AUTOSAR XML (schema 00046)
package /ComponentTypes
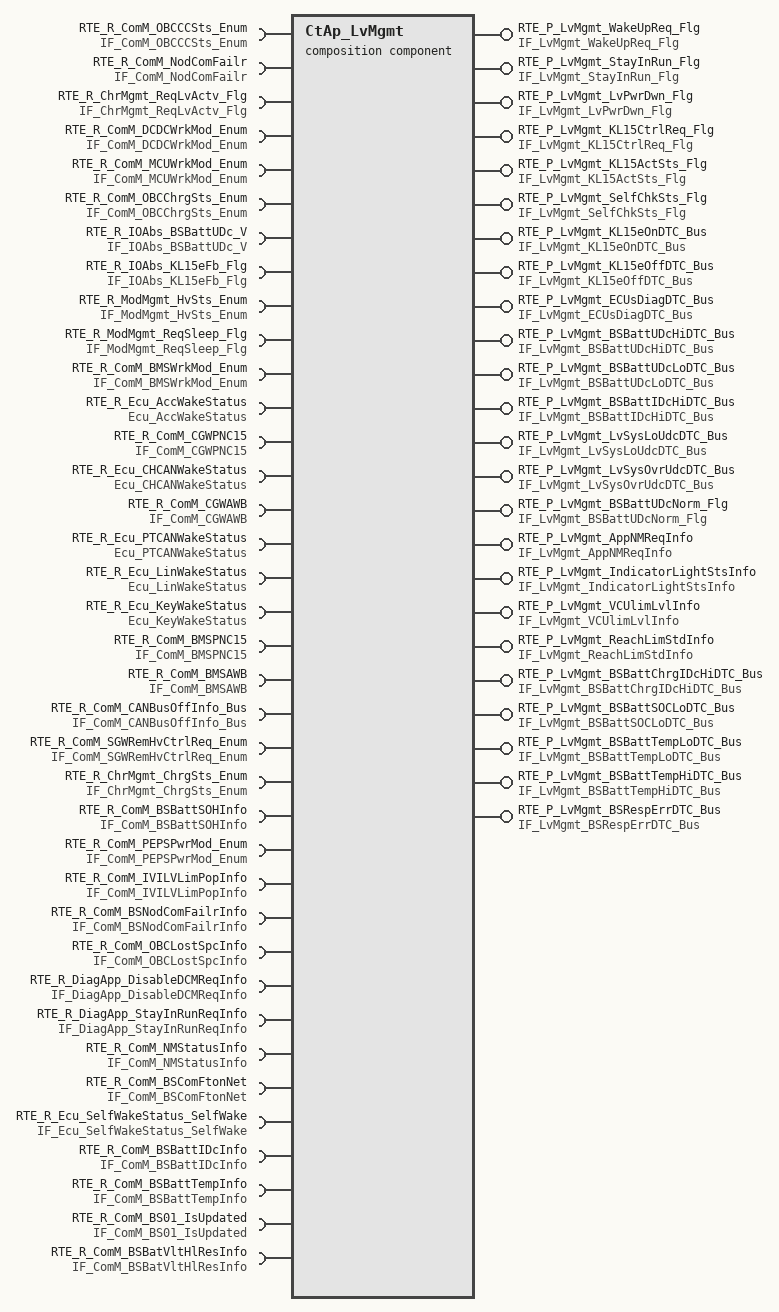
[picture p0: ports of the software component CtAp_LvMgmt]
  composition sw component type CtAp_LvMgmt
    provide port RTE_P_LvMgmt_WakeUpReq_Flg: nonqueued-sender-com-spec{data-element=tec_LvMgmt_WakeUpReq_Flg, init-value=0}, provided-interface=IF_LvMgmt_WakeUpReq_Flg
    require port RTE_R_ComM_OBCCCSts_Enum: nonqueued-receiver-com-spec{data-element=tec_ComM_OBCCCSts_Enum, filter=data-filter-type=ALWAYS, init-value=0}, required-interface=IF_ComM_OBCCCSts_Enum
    require port RTE_R_ComM_NodComFailr: required-interface=IF_ComM_NodComFailr
      required-com-specs:
        data-element=tec_ComM_SGWNodComFailr_Flg, filter=data-filter-type=ALWAYS, init-value=0
        data-element=tec_ComM_CGWNodComFailr_Flg, filter=data-filter-type=ALWAYS, init-value=0
        data-element=tec_ComM_TCUNodComFailr_Flg, filter=data-filter-type=ALWAYS, init-value=0
        data-element=tec_ComM_BCMNodComFailr_Flg, filter=data-filter-type=ALWAYS, init-value=0
        data-element=tec_ComM_PRNDNodComFailr_Flg, filter=data-filter-type=ALWAYS, init-value=0
        data-element=tec_ComM_IVINodComFailr_Flg, filter=data-filter-type=ALWAYS, init-value=0
        data-element=tec_ComM_DCDCNodComFailr_Flg, filter=data-filter-type=ALWAYS, init-value=0
        data-element=tec_ComM_OBCNodComFailr_Flg, filter=data-filter-type=ALWAYS, init-value=0
        data-element=tec_ComM_CHIBSNodComFailr_Flg, filter=data-filter-type=ALWAYS, init-value=0
        data-element=tec_ComM_MCUNodComFailr_Flg, filter=data-filter-type=ALWAYS, init-value=0
        data-element=tec_ComM_EVCOMNodComFailr_Flg, filter=data-filter-type=ALWAYS, init-value=0
        data-element=tec_ComM_EPTIBSNodComFailr_Flg, filter=data-filter-type=ALWAYS, init-value=0
        data-element=tec_ComM_DCMNodComFailr_Flg, filter=data-filter-type=ALWAYS, init-value=0
        data-element=tec_ComM_BMSNodComFailr_Flg, filter=data-filter-type=ALWAYS, init-value=0
        data-element=tec_ComM_ACUNodComFailr_Flg, filter=data-filter-type=ALWAYS, init-value=0
        data-element=tec_ComM_APTCNodComFailr_Flg, filter=data-filter-type=ALWAYS, init-value=0
        data-element=tec_ComM_ADCUNodComFailr_Flg, filter=data-filter-type=ALWAYS, init-value=0
        data-element=tec_ComM_DCMRRNodComFailr_Flg, filter=data-filter-type=ALWAYS, init-value=0
        data-element=tec_ComM_DCMRLNodComFailr_Flg, filter=data-filter-type=ALWAYS, init-value=0
        data-element=tec_ComM_DCMFRNodComFailr_Flg, filter=data-filter-type=ALWAYS, init-value=0
        data-element=tec_ComM_DCMFLNodComFailr_Flg, filter=data-filter-type=ALWAYS, init-value=0
        data-element=tec_ComM_SGWCHNodComFailr_Flg, filter=data-filter-type=ALWAYS, init-value=0
    require port RTE_R_ChrMgmt_ReqLvActv_Flg: nonqueued-receiver-com-spec{data-element=tec_ChrMgmt_ReqLvActv_Flg, filter=data-filter-type=ALWAYS, init-value=0}, required-interface=IF_ChrMgmt_ReqLvActv_Flg
    13 x provide port:
      RTE_P_LvMgmt_StayInRun_Flg: nonqueued-sender-com-spec{data-element=tec_LvMgmt_StayInRun_Flg, init-value=0}, provided-interface=IF_LvMgmt_StayInRun_Flg
      RTE_P_LvMgmt_LvPwrDwn_Flg: nonqueued-sender-com-spec{data-element=tec_LvMgmt_LvPwrDwn_Flg, init-value=0}, provided-interface=IF_LvMgmt_LvPwrDwn_Flg
      RTE_P_LvMgmt_KL15CtrlReq_Flg: nonqueued-sender-com-spec{data-element=tec_LvMgmt_KL15CtrlReq_Flg, init-value=0}, provided-interface=IF_LvMgmt_KL15CtrlReq_Flg
      RTE_P_LvMgmt_KL15ActSts_Flg: nonqueued-sender-com-spec{data-element=tec_LvMgmt_KL15ActSts_Flg, init-value=0}, provided-interface=IF_LvMgmt_KL15ActSts_Flg
      RTE_P_LvMgmt_SelfChkSts_Flg: nonqueued-sender-com-spec{data-element=tec_LvMgmt_SelfChkSts_Flg, init-value=0}, provided-interface=IF_LvMgmt_SelfChkSts_Flg
      RTE_P_LvMgmt_KL15eOnDTC_Bus: nonqueued-sender-com-spec{data-element=tec_LvMgmt_KL15eOnDTC_Bus, init-value=fields=[LvMgmt_MonStatKL15eOnDTC_:0, LvMgmt_MonResKL15eOnDTC:0, LvMgmt_ErrStatKL15eOnDTC:0, LvMgmt_ErrResKL15eOnDTC:0]}, provided-interface=IF_LvMgmt_KL15eOnDTC_Bus
      RTE_P_LvMgmt_KL15eOffDTC_Bus: nonqueued-sender-com-spec{data-element=tec_LvMgmt_KL15eOffDTC_Bus, init-value=fields=[LvMgmt_MonStatKL15eOffDTC:0, LvMgmt_MonResKL15eOffDTC:0, LvMgmt_ErrStatKL15eOffDTC:0, LvMgmt_ErrResKL15eOffDTC:0]}, provided-interface=IF_LvMgmt_KL15eOffDTC_Bus
      RTE_P_LvMgmt_ECUsDiagDTC_Bus: nonqueued-sender-com-spec{data-element=tec_LvMgmt_ECUsDiagDTC_Bus, init-value=fields=[LvMgmt_MonStatECUsDiagDTC:0, LvMgmt_MonResECUsDiagDTC:0, LvMgmt_ErrStatECUsDiagDTC:0, LvMgmt_ErrResECUsDiagDTC:0]}, provided-interface=IF_LvMgmt_ECUsDiagDTC_Bus
      RTE_P_LvMgmt_BSBattUDcHiDTC_Bus: nonqueued-sender-com-spec{data-element=tec_LvMgmt_BSBattUDcHiDTC_Bus, init-value=fields=[LvMgmt_MonStatBSBattUDcHiDTC:0, LvMgmt_MonResBSBattUDcHiDTC:0, LvMgmt_ErrStatBSBattUDcHiDTC:0, LvMgmt_ErrResBSBattUDcHiDTC:0]}, provided-interface=IF_LvMgmt_BSBattUDcHiDTC_Bus
      RTE_P_LvMgmt_BSBattUDcLoDTC_Bus: nonqueued-sender-com-spec{data-element=tec_LvMgmt_BSBattUDcLoDTC_Bus, init-value=fields=[LvMgmt_MonStatBSBattUDcLoDTC:0, LvMgmt_MonResBSBattUDcLoDTC:0, LvMgmt_ErrStatBSBattUDcLoDTC:0, LvMgmt_ErrResBSBattUDcLoDTC:0]}, provided-interface=IF_LvMgmt_BSBattUDcLoDTC_Bus
      RTE_P_LvMgmt_BSBattIDcHiDTC_Bus: nonqueued-sender-com-spec{data-element=tec_LvMgmt_BSBattIDcHiDTC_Bus, init-value=fields=[LvMgmt_MonStatBSBattIDcHiDTC:0, LvMgmt_MonResBSBattIDcHiDTC:0, LvMgmt_ErrStatBSBattIDcHiDTC:0, LvMgmt_ErrResBSBattIDcHiDTC:0]}, provided-interface=IF_LvMgmt_BSBattIDcHiDTC_Bus
      RTE_P_LvMgmt_LvSysLoUdcDTC_Bus: nonqueued-sender-com-spec{data-element=tec_LvMgmt_LvSysLoUdcDTC_Bus, init-value=fields=[LvMgmt_MonStatLvSysLoUDcDTC:0, LvMgmt_MonResLvSysLoUDcDTC:0, LvMgmt_ErrStatLvSysLoUDcDTC:0, LvMgmt_ErrResLvSysLoUDcDTC:0]}, provided-interface=IF_LvMgmt_LvSysLoUdcDTC_Bus
      RTE_P_LvMgmt_LvSysOvrUdcDTC_Bus: nonqueued-sender-com-spec{data-element=tec_LvMgmt_LvSysOvrUdcDTC_Bus, init-value=fields=[LvMgmt_MonStatLvSysOvrUDcDTC:0, LvMgmt_MonResLvSysOvrUDcDTC:0, LvMgmt_ErrStatLvSysOvrUDcDTC:0, LvMgmt_ErrResLvSysOvrUDcDTC:0]}, provided-interface=IF_LvMgmt_LvSysOvrUdcDTC_Bus
    8 x require port:
      RTE_R_ComM_DCDCWrkMod_Enum: nonqueued-receiver-com-spec{data-element=tec_ComM_DCDCWrkMod_Enum, filter=data-filter-type=ALWAYS, init-value=0}, required-interface=IF_ComM_DCDCWrkMod_Enum
      RTE_R_ComM_MCUWrkMod_Enum: nonqueued-receiver-com-spec{data-element=tec_ComM_MCUWrkMod_Enum, filter=data-filter-type=ALWAYS, init-value=0}, required-interface=IF_ComM_MCUWrkMod_Enum
      RTE_R_ComM_OBCChrgSts_Enum: nonqueued-receiver-com-spec{data-element=tec_ComM_OBCChrgSts_Enum, filter=data-filter-type=ALWAYS, init-value=0}, required-interface=IF_ComM_OBCChrgSts_Enum
      RTE_R_IOAbs_BSBattUDc_V: nonqueued-receiver-com-spec{data-element=tec_IOAbs_BSBattUDc_V, filter=data-filter-type=ALWAYS, init-value=0}, required-interface=IF_IOAbs_BSBattUDc_V
      RTE_R_IOAbs_KL15eFb_Flg: nonqueued-receiver-com-spec{data-element=tec_IOAbs_KL15eFb_Flg, filter=data-filter-type=ALWAYS, init-value=0}, required-interface=IF_IOAbs_KL15eFb_Flg
      RTE_R_ModMgmt_HvSts_Enum: nonqueued-receiver-com-spec{data-element=tec_ModMgmt_HvSts_Enum, filter=data-filter-type=ALWAYS, init-value=0}, required-interface=IF_ModMgmt_HvSts_Enum
      RTE_R_ModMgmt_ReqSleep_Flg: nonqueued-receiver-com-spec{data-element=tec_ModMgmt_ReqSleep_Flg, filter=data-filter-type=ALWAYS, init-value=0}, required-interface=IF_ModMgmt_ReqSleep_Flg
      RTE_R_ComM_BMSWrkMod_Enum: nonqueued-receiver-com-spec{data-element=tec_ComM_BMSWrkMod_Enum, filter=data-filter-type=ALWAYS, init-value=0}, required-interface=IF_ComM_BMSWrkMod_Enum
    provide port RTE_P_LvMgmt_BSBattUDcNorm_Flg: nonqueued-sender-com-spec{data-element=tec_LvMgmt_BSBattUDcNorm_Flg, init-value=0}, provided-interface=IF_LvMgmt_BSBattUDcNorm_Flg
    10 x require port:
      RTE_R_Ecu_AccWakeStatus: nonqueued-receiver-com-spec{data-element=Accwake, filter=data-filter-type=ALWAYS, init-value=0}, required-interface=Ecu_AccWakeStatus
      RTE_R_ComM_CGWPNC15: nonqueued-receiver-com-spec{data-element=tec_ComM_CGWPNC15, filter=data-filter-type=ALWAYS, init-value=0}, required-interface=IF_ComM_CGWPNC15
      RTE_R_Ecu_CHCANWakeStatus: nonqueued-receiver-com-spec{data-element=CHCANwake, filter=data-filter-type=ALWAYS, init-value=0}, required-interface=Ecu_CHCANWakeStatus
      RTE_R_ComM_CGWAWB: nonqueued-receiver-com-spec{data-element=tec_ComM_CGWAWB, filter=data-filter-type=ALWAYS, init-value=0}, required-interface=IF_ComM_CGWAWB
      RTE_R_Ecu_PTCANWakeStatus: nonqueued-receiver-com-spec{data-element=PTCANwake, filter=data-filter-type=ALWAYS, init-value=0}, required-interface=Ecu_PTCANWakeStatus
      RTE_R_Ecu_LinWakeStatus: nonqueued-receiver-com-spec{data-element=Linwake, filter=data-filter-type=ALWAYS, init-value=0}, required-interface=Ecu_LinWakeStatus
      RTE_R_Ecu_KeyWakeStatus: nonqueued-receiver-com-spec{data-element=Keywake, filter=data-filter-type=ALWAYS, init-value=0}, required-interface=Ecu_KeyWakeStatus
      RTE_R_ComM_BMSPNC15: nonqueued-receiver-com-spec{data-element=tec_ComM_BMSPNC15, filter=data-filter-type=ALWAYS, init-value=0}, required-interface=IF_ComM_BMSPNC15
      RTE_R_ComM_BMSAWB: nonqueued-receiver-com-spec{data-element=tec_ComM_BMSAWB, filter=data-filter-type=ALWAYS, init-value=0}, required-interface=IF_ComM_BMSAWB
      RTE_R_ComM_CANBusOffInfo_Bus: required-interface=IF_ComM_CANBusOffInfo_Bus
        required-com-specs:
          data-element=tec_ComM_EPTCANBusOffInfo_Bus, filter=data-filter-type=ALWAYS, init-value=fields=[ComM_MonStatEPTCANBusOffInfo:0, ComM_MonResEPTCANBusOffInfo:0, ComM_ErrStatEPTCANBusOffInfo:0, ComM_ErrResEPTCANBusOffInfo:0]
          data-element=tec_ComM_CHCANBusOffInfo_Bus, filter=data-filter-type=ALWAYS, init-value=fields=[ComM_MonStatCHCANBusOffInfo:0, ComM_MonResCHCANBusOffInfo:0, ComM_ErrStatCHCANBusOffInfo:0, ComM_ErrResCHCANBusOffInfo:0]
          data-element=tec_ComM_EPTCANBusOffDTCInfo_Bus, filter=data-filter-type=ALWAYS, init-value=fields=[ComM_MonStatEPTCANBusOffDTCInfo:0, ComM_MonResEPTCANBusOffDTCInfo:0, ComM_ErrStatEPTCANBusOffDTCInfo:0, ComM_ErrResEPTCANBusOffDTCInfo:0]
          data-element=tec_ComM_CHCANBusOffDTCInfo_Bus, filter=data-filter-type=ALWAYS, init-value=fields=[ComM_MonStatCHCANBusOffDTCInfo:0, ComM_MonResCHCANBusOffDTCInfo:0, ComM_ErrStatCHCANBusOffDTCInfo:0, ComM_ErrResCHCANBusOffDTCInfo:0]
          data-element=tec_ComM_DCCANBusOffDTCInfo_Bus, filter=data-filter-type=ALWAYS
          data-element=tec_ComM_DCCANBusOffInfo_Bus, filter=data-filter-type=ALWAYS
    provide port RTE_P_LvMgmt_AppNMReqInfo: nonqueued-sender-com-spec{data-element=tec_LvMgmt_AppNMReqInfo, init-value=0}, provided-interface=IF_LvMgmt_AppNMReqInfo
    6 x require port:
      RTE_R_ComM_SGWRemHvCtrlReq_Enum: nonqueued-receiver-com-spec{data-element=tec_ComM_SGWRemHvCtrlReq_Enum, filter=data-filter-type=ALWAYS, init-value=0}, required-interface=IF_ComM_SGWRemHvCtrlReq_Enum
      RTE_R_ChrMgmt_ChrgSts_Enum: nonqueued-receiver-com-spec{data-element=tec_ChrMgmt_ChrgSts_Enum, filter=data-filter-type=ALWAYS, init-value=0}, required-interface=IF_ChrMgmt_ChrgSts_Enum
      RTE_R_ComM_BSBattSOHInfo: nonqueued-receiver-com-spec{data-element=tec_ComM_BSBattSOHInfo, filter=data-filter-type=ALWAYS, init-value=0}, required-interface=IF_ComM_BSBattSOHInfo
      RTE_R_ComM_PEPSPwrMod_Enum: nonqueued-receiver-com-spec{data-element=tec_ComM_PEPSPwrMod_Enum, filter=data-filter-type=ALWAYS, init-value=0}, required-interface=IF_ComM_PEPSPwrMod_Enum
      RTE_R_ComM_IVILVLimPopInfo: nonqueued-receiver-com-spec{data-element=tec_ComM_IVILVLimPopInfo, filter=data-filter-type=ALWAYS, init-value=0}, required-interface=IF_ComM_IVILVLimPopInfo
      RTE_R_ComM_BSNodComFailrInfo: nonqueued-receiver-com-spec{data-element=tec_ComM_BSNodComFailrInfo, filter=data-filter-type=ALWAYS, init-value=0}, required-interface=IF_ComM_BSNodComFailrInfo
    provide port RTE_P_LvMgmt_IndicatorLightStsInfo: nonqueued-sender-com-spec{data-element=tec_LvMgmt_IndicatorLightStsInfo, init-value=0}, provided-interface=IF_LvMgmt_IndicatorLightStsInfo
    provide port RTE_P_LvMgmt_VCUlimLvlInfo: nonqueued-sender-com-spec{data-element=tec_LvMgmt_VCUlimLvlInfo, init-value=0}, provided-interface=IF_LvMgmt_VCUlimLvlInfo
    provide port RTE_P_LvMgmt_ReachLimStdInfo: nonqueued-sender-com-spec{data-element=tec_LvMgmt_ReachLimStdInfo, init-value=0}, provided-interface=IF_LvMgmt_ReachLimStdInfo
    4 x require port:
      RTE_R_ComM_OBCLostSpcInfo: nonqueued-receiver-com-spec{data-element=tec_ComM_OBCLostSpcInfo, filter=data-filter-type=ALWAYS, init-value=0}, required-interface=IF_ComM_OBCLostSpcInfo
      RTE_R_DiagApp_DisableDCMReqInfo: nonqueued-receiver-com-spec{data-element=tec_DiagApp_DisableDCMReqInfo, filter=data-filter-type=ALWAYS, init-value=0}, required-interface=IF_DiagApp_DisableDCMReqInfo
      RTE_R_DiagApp_StayInRunReqInfo: nonqueued-receiver-com-spec{data-element=tec_DiagApp_StayInRunReqInfo, filter=data-filter-type=ALWAYS, init-value=0}, required-interface=IF_DiagApp_StayInRunReqInfo
      RTE_R_ComM_NMStatusInfo: nonqueued-receiver-com-spec{data-element=tec_ComM_NMStatusInfo, filter=data-filter-type=ALWAYS, init-value=0}, required-interface=IF_ComM_NMStatusInfo
    5 x provide port:
      RTE_P_LvMgmt_BSBattChrgIDcHiDTC_Bus: nonqueued-sender-com-spec{data-element=tec_LvMgmt_BSBattChrgIDcHiDTC_Bus, init-value=fields=[LvMgmt_MonStatBSBattChrgIDcHiDTC:0, LvMgmt_MonResBSBattChrgIDcHiDTC:0, LvMgmt_ErrStatBSBattChrgIDcHiDTC:0, LvMgmt_ErrResBSBattChrgIDcHiDTC:0]}, provided-interface=IF_LvMgmt_BSBattChrgIDcHiDTC_Bus
      RTE_P_LvMgmt_BSBattSOCLoDTC_Bus: nonqueued-sender-com-spec{data-element=tec_LvMgmt_BSBattSOCLoDTC_Bus, init-value=fields=[LvMgmt_MonStatBSBattSOCLoDTC:0, LvMgmt_MonResBSBattSOCLoDTC:0, LvMgmt_ErrStatBSBattSOCLoDTC:0, LvMgmt_ErrResBSBattSOCLoDTC:0]}, provided-interface=IF_LvMgmt_BSBattSOCLoDTC_Bus
      RTE_P_LvMgmt_BSBattTempLoDTC_Bus: nonqueued-sender-com-spec{data-element=tec_LvMgmt_BSBattTempLoDTC_Bus, init-value=fields=[LvMgmt_MonStatBSBattTempLoDTC:0, LvMgmt_MonResBSBattTempLoDTC:0, LvMgmt_ErrStatBSBattTempLoDTC:0, LvMgmt_ErrResBSBattTempLoDTC:0]}, provided-interface=IF_LvMgmt_BSBattTempLoDTC_Bus
      RTE_P_LvMgmt_BSBattTempHiDTC_Bus: nonqueued-sender-com-spec{data-element=tec_LvMgmt_BSBattTempHiDTC_Bus, init-value=fields=[LvMgmt_MonStatBSBattTempHiDTC:0, LvMgmt_MonResBSBattTempHiDTC:0, LvMgmt_ErrStatBSBattTempHiDTC:0, LvMgmt_ErrResBSBattTempHiDTC:0]}, provided-interface=IF_LvMgmt_BSBattTempHiDTC_Bus
      RTE_P_LvMgmt_BSRespErrDTC_Bus: nonqueued-sender-com-spec{data-element=tec_LvMgmt_BSRespErrDTC_Bus, init-value=fields=[LvMgmt_MonStatBSRespErrDTC:0, LvMgmt_MonResBSRespErrDTC:0, LvMgmt_ErrStatBSRespErrDTC:0, LvMgmt_ErrResBSRespErrDTC:0]}, provided-interface=IF_LvMgmt_BSRespErrDTC_Bus
    6 x require port:
      RTE_R_ComM_BSComFtonNet: nonqueued-receiver-com-spec{data-element=tec_ComM_BSComFtonNet, filter=data-filter-type=ALWAYS, init-value=0}, required-interface=IF_ComM_BSComFtonNet
      RTE_R_Ecu_SelfWakeStatus_SelfWake: nonqueued-receiver-com-spec{data-element=tec_Ecu_SelfWakeStatus_SelfWake, filter=data-filter-type=ALWAYS, init-value=0}, required-interface=IF_Ecu_SelfWakeStatus_SelfWake
      RTE_R_ComM_BSBattIDcInfo: nonqueued-receiver-com-spec{data-element=tec_ComM_BSBattIDcInfo, filter=data-filter-type=ALWAYS, init-value=0}, required-interface=IF_ComM_BSBattIDcInfo
      RTE_R_ComM_BSBattTempInfo: nonqueued-receiver-com-spec{data-element=tec_ComM_BSBattTempInfo, filter=data-filter-type=ALWAYS, init-value=0}, required-interface=IF_ComM_BSBattTempInfo
      RTE_R_ComM_BS01_IsUpdated: nonqueued-receiver-com-spec{data-element=tec_ComM_BS01_IsUpdated, filter=data-filter-type=ALWAYS, init-value=0}, required-interface=IF_ComM_BS01_IsUpdated
      RTE_R_ComM_BSBatVltHlResInfo: nonqueued-receiver-com-spec{data-element=tec_ComM_BSBatVltHlResInfo, filter=data-filter-type=ALWAYS, init-value=0}, required-interface=IF_ComM_BSBatVltHlResInfo
    component CtAp_ElSSDiag: type=CtAp_ElSSDiag
    component CtAp_WakeUpRsn: type=CtAp_WakeUpRsn
    component CtAp_LvBattMgmt: type=CtAp_LvBattMgmt
    delegate CtAp_WakeUpRsn.RTE_P_LvMgmt_WakeUpReq_Flg <-> outer port RTE_P_LvMgmt_WakeUpReq_Flg
    delegate CtAp_WakeUpRsn.RTE_R_ComM_OBCCCSts_Enum <-> outer port RTE_R_ComM_OBCCCSts_Enum
    delegate CtAp_WakeUpRsn.RTE_R_ChrMgmt_ReqLvActv_Flg <-> outer port RTE_R_ChrMgmt_ReqLvActv_Flg
    delegate CtAp_ElSSDiag.RTE_R_IOAbs_KL15eFb_Flg <-> outer port RTE_R_IOAbs_KL15eFb_Flg
    delegate CtAp_ElSSDiag.RTE_R_ComM_DCDCWrkMod_Enum <-> outer port RTE_R_ComM_DCDCWrkMod_Enum
    delegate CtAp_ElSSDiag.RTE_R_ComM_OBCChrgSts_Enum <-> outer port RTE_R_ComM_OBCChrgSts_Enum
    delegate CtAp_ElSSDiag.RTE_R_ComM_MCUWrkMod_Enum <-> outer port RTE_R_ComM_MCUWrkMod_Enum
    delegate CtAp_ElSSDiag.RTE_R_ModMgmt_HvSts_Enum <-> outer port RTE_R_ModMgmt_HvSts_Enum
    delegate CtAp_ElSSDiag.RTE_R_ModMgmt_ReqSleep_Flg <-> outer port RTE_R_ModMgmt_ReqSleep_Flg
    connect CtAp_WakeUpRsn.RTE_P_LvMgmt_WakeUpReq_Flg -> CtAp_ElSSDiag.RTE_R_LvMgmt_WakeUpReq_Flg
    delegate CtAp_ElSSDiag.RTE_P_LvMgmt_StayInRun_Flg <-> outer port RTE_P_LvMgmt_StayInRun_Flg
    delegate CtAp_ElSSDiag.RTE_P_LvMgmt_KL15eOffDTC_Bus <-> outer port RTE_P_LvMgmt_KL15eOffDTC_Bus
    delegate CtAp_LvBattMgmt.RTE_P_LvMgmt_LvSysOvrUdcDTC_Bus <-> outer port RTE_P_LvMgmt_LvSysOvrUdcDTC_Bus
    delegate CtAp_ElSSDiag.RTE_P_LvMgmt_ECUsDiagDTC_Bus <-> outer port RTE_P_LvMgmt_ECUsDiagDTC_Bus
    delegate CtAp_ElSSDiag.RTE_P_LvMgmt_KL15eOnDTC_Bus <-> outer port RTE_P_LvMgmt_KL15eOnDTC_Bus
    delegate CtAp_ElSSDiag.RTE_P_LvMgmt_KL15CtrlReq_Flg <-> outer port RTE_P_LvMgmt_KL15CtrlReq_Flg
    delegate CtAp_LvBattMgmt.RTE_P_LvMgmt_BSBattUDcLoDTC_Bus <-> outer port RTE_P_LvMgmt_BSBattUDcLoDTC_Bus
    delegate CtAp_LvBattMgmt.RTE_P_LvMgmt_BSBattUDcHiDTC_Bus <-> outer port RTE_P_LvMgmt_BSBattUDcHiDTC_Bus
    delegate CtAp_ElSSDiag.RTE_P_LvMgmt_SelfChkSts_Flg <-> outer port RTE_P_LvMgmt_SelfChkSts_Flg
    delegate CtAp_LvBattMgmt.RTE_P_LvMgmt_BSBattIDcHiDTC_Bus <-> outer port RTE_P_LvMgmt_BSBattIDcHiDTC_Bus
    delegate CtAp_ElSSDiag.RTE_P_LvMgmt_LvPwrDwn_Flg <-> outer port RTE_P_LvMgmt_LvPwrDwn_Flg
    delegate CtAp_ElSSDiag.RTE_P_LvMgmt_KL15ActSts_Flg <-> outer port RTE_P_LvMgmt_KL15ActSts_Flg
    delegate CtAp_ElSSDiag.RTE_R_ComM_BMSWrkMod_Enum <-> outer port RTE_R_ComM_BMSWrkMod_Enum
    delegate CtAp_LvBattMgmt.RTE_P_LvMgmt_LvSysLoUdcDTC_Bus <-> outer port RTE_P_LvMgmt_LvSysLoUdcDTC_Bus
    delegate CtAp_LvBattMgmt.RTE_P_LvMgmt_BSBattUDcNorm_Flg <-> outer port RTE_P_LvMgmt_BSBattUDcNorm_Flg
    connect CtAp_LvBattMgmt.RTE_P_LvMgmt_BSBattUDcNorm_Flg -> CtAp_ElSSDiag.RTE_R_LvMgmt_BSBattUDcNorm_Flg
    delegate CtAp_LvBattMgmt.RTE_R_IOAbs_BSBattUDc_V <-> outer port RTE_R_IOAbs_BSBattUDc_V
    delegation sw connector RTE_R_ComM_BSBattSOC_pct_CtAp_LvBattMgmt_RTE_R_ComM_BSBattSOC_pct: inner-port=CtAp_LvBattMgmt.RTE_R_ComM_BSBattSOC_pct
    delegate CtAp_WakeUpRsn.RTE_R_Ecu_AccWakeStatus <-> outer port RTE_R_Ecu_AccWakeStatus
    delegate CtAp_WakeUpRsn.RTE_R_ComM_CGWPNC15 <-> outer port RTE_R_ComM_CGWPNC15
    delegate CtAp_WakeUpRsn.RTE_R_Ecu_CHCANWakeStatus <-> outer port RTE_R_Ecu_CHCANWakeStatus
    delegate CtAp_WakeUpRsn.RTE_R_ComM_CGWAWB <-> outer port RTE_R_ComM_CGWAWB
    delegate CtAp_WakeUpRsn.RTE_R_Ecu_PTCANWakeStatus <-> outer port RTE_R_Ecu_PTCANWakeStatus
    delegate CtAp_WakeUpRsn.RTE_R_Ecu_LinWakeStatus <-> outer port RTE_R_Ecu_LinWakeStatus
    delegate CtAp_WakeUpRsn.RTE_R_Ecu_KeyWakeStatus <-> outer port RTE_R_Ecu_KeyWakeStatus
    delegate CtAp_WakeUpRsn.RTE_R_ComM_BMSPNC15 <-> outer port RTE_R_ComM_BMSPNC15
    delegate CtAp_WakeUpRsn.RTE_R_ComM_BMSAWB <-> outer port RTE_R_ComM_BMSAWB
    delegate CtAp_ElSSDiag.RTE_R_ComM_CANBusOffInfo_Bus <-> outer port RTE_R_ComM_CANBusOffInfo_Bus
    delegate CtAp_WakeUpRsn.RTE_P_LvMgmt_AppNMReqInfo <-> outer port RTE_P_LvMgmt_AppNMReqInfo
    delegate CtAp_WakeUpRsn.RTE_R_ComM_SGWRemHvCtrlReq_Enum <-> outer port RTE_R_ComM_SGWRemHvCtrlReq_Enum
    delegate CtAp_WakeUpRsn.RTE_R_ChrMgmt_ChrgSts_Enum <-> outer port RTE_R_ChrMgmt_ChrgSts_Enum
    delegate CtAp_WakeUpRsn.RTE_R_ModMgmt_HvSts_Enum <-> outer port RTE_R_ModMgmt_HvSts_Enum
    delegate CtAp_LvBattMgmt.RTE_R_ComM_BSBattSOHInfo <-> outer port RTE_R_ComM_BSBattSOHInfo
    delegate CtAp_LvBattMgmt.RTE_R_ComM_PEPSPwrMod_Enum <-> outer port RTE_R_ComM_PEPSPwrMod_Enum
    delegate CtAp_LvBattMgmt.RTE_R_ComM_NodComFailr <-> outer port RTE_R_ComM_NodComFailr
    delegate CtAp_LvBattMgmt.RTE_R_ComM_IVILVLimPopInfo <-> outer port RTE_R_ComM_IVILVLimPopInfo
    delegate CtAp_LvBattMgmt.RTE_R_ComM_BSNodComFailrInfo <-> outer port RTE_R_ComM_BSNodComFailrInfo
    delegate CtAp_LvBattMgmt.RTE_P_LvMgmt_IndicatorLightStsInfo <-> outer port RTE_P_LvMgmt_IndicatorLightStsInfo
    delegate CtAp_LvBattMgmt.RTE_P_LvMgmt_VCUlimLvlInfo <-> outer port RTE_P_LvMgmt_VCUlimLvlInfo
    delegate CtAp_LvBattMgmt.RTE_P_LvMgmt_ReachLimStdInfo <-> outer port RTE_P_LvMgmt_ReachLimStdInfo
    delegate CtAp_ElSSDiag.RTE_R_ComM_OBCLostSpcInfo <-> outer port RTE_R_ComM_OBCLostSpcInfo
    delegate CtAp_ElSSDiag.RTE_R_DiagApp_DisableDCMReqInfo <-> outer port RTE_R_DiagApp_DisableDCMReqInfo
    delegate CtAp_LvBattMgmt.RTE_R_DiagApp_DisableDCMReqInfo <-> outer port RTE_R_DiagApp_DisableDCMReqInfo
    delegate CtAp_WakeUpRsn.RTE_R_ComM_NMStatusInfo <-> outer port RTE_R_ComM_NMStatusInfo
    delegate CtAp_LvBattMgmt.RTE_P_LvMgmt_BSBattChrgIDcHiDTC_Bus <-> outer port RTE_P_LvMgmt_BSBattChrgIDcHiDTC_Bus
    delegate CtAp_LvBattMgmt.RTE_P_LvMgmt_BSBattSOCLoDTC_Bus <-> outer port RTE_P_LvMgmt_BSBattSOCLoDTC_Bus
    delegate CtAp_LvBattMgmt.RTE_P_LvMgmt_BSBattTempLoDTC_Bus <-> outer port RTE_P_LvMgmt_BSBattTempLoDTC_Bus
    delegate CtAp_LvBattMgmt.RTE_P_LvMgmt_BSBattTempHiDTC_Bus <-> outer port RTE_P_LvMgmt_BSBattTempHiDTC_Bus
    delegate CtAp_LvBattMgmt.RTE_P_LvMgmt_BSRespErrDTC_Bus <-> outer port RTE_P_LvMgmt_BSRespErrDTC_Bus
    connect CtAp_WakeUpRsn.RTE_P_LvMgmt_AppNMReqInfo -> CtAp_ElSSDiag.RTE_R_LvMgmt_AppNMReqInfo
    delegate CtAp_LvBattMgmt.RTE_R_ComM_BSComFtonNet <-> outer port RTE_R_ComM_BSComFtonNet
    delegation sw connector RTE_R_ComM_BSBattSOC_pct_CtAp_WakeUpRsn_RTE_R_ComM_BSBattSOC_pct: inner-port=CtAp_WakeUpRsn
    delegate CtAp_WakeUpRsn.RTE_R_DiagApp_StayInRunReqInfo <-> outer port RTE_R_DiagApp_StayInRunReqInfo
    delegate CtAp_WakeUpRsn.RTE_R_Ecu_SelfWakeStatus_SelfWake <-> outer port RTE_R_Ecu_SelfWakeStatus_SelfWake
    delegate CtAp_LvBattMgmt.RTE_R_ComM_BSBattIDcInfo <-> outer port RTE_R_ComM_BSBattIDcInfo
    delegate CtAp_LvBattMgmt.RTE_R_ComM_BSBattTempInfo <-> outer port RTE_R_ComM_BSBattTempInfo
    delegate CtAp_LvBattMgmt.RTE_R_ComM_BS01_IsUpdated <-> outer port RTE_R_ComM_BS01_IsUpdated
    delegate CtAp_LvBattMgmt.RTE_R_ComM_BSBatVltHlResInfo <-> outer port RTE_R_ComM_BSBatVltHlResInfo
